# STM32U585xx register map
File version: 1.0
Registers are 32-bit, read-write, reset 0x0 unless marked. A register's access mark holds for its fields unless they carry their own. Offsets are from the block's base; [hi:lo] are bit positions; {n}, {i} and the like mark numbered series.

## PSSI
Base 0x4202C400
Same registers: PSSI_S 0x5202C400
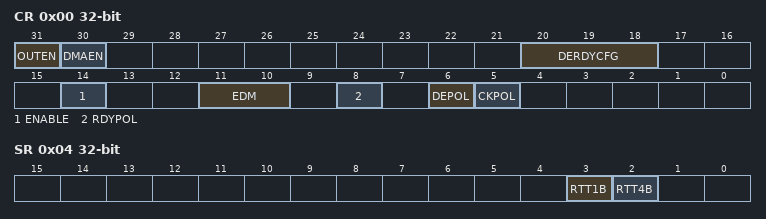
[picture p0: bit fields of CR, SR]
0x00 CR — PSSI control register
  [31] OUTEN — Data direction selection
  [30] DMAEN — DMA enable
  [20:18] DERDYCFG — Data enable and ready configuration
  [14] ENABLE — PSSI enable
  [11:10] EDM — Extended data mode
  [8] RDYPOL — Ready polarity
  [6] DEPOL — Data enable polarity
  [5] CKPOL — Parallel data clock polarity
0x04 SR — PSSI status register
  [3] RTT1B — Ready to transfer one byte
  [2] RTT4B — Ready to transfer four bytes
0x08 RIS — PSSI raw interrupt status register
  [1] OVR_RIS — Data buffer overrun/underrun raw interrupt status
0x0C IER — PSSI interrupt enable register
  [1] OVR_IE — Data buffer overrun/underrun interrupt enable
0x10 MIS — PSSI masked interrupt status register
  [1] OVR_MIS — Data buffer overrun/underrun masked interrupt status
0x14 ICR — PSSI interrupt clear register
  [1] OVR_ISC — Data buffer overrun/underrun interrupt status clear
0x28 DR — PSSI data register
  [31:0] DR — Data register

## AES — AES hardware accelerator
Base 0x420C0000
Same registers: SAES 0x420C0C00, AES_S 0x520C0000, SAES_S 0x520C0C00
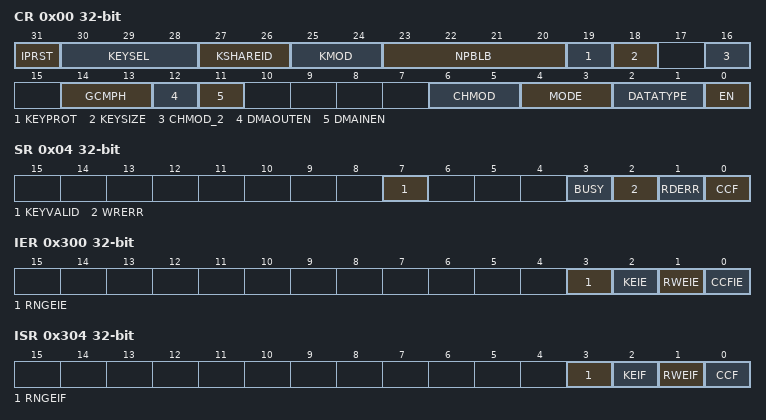
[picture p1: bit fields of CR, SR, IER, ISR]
0x00 CR — AES control register
  [31] IPRST — AES IP software reset
  [30:28] KEYSEL — Key Selection
  [27:26] KSHAREID — Key Shared ID
  [25:24] KMOD — Key mode selection
  [23:20] NPBLB — Number of padding bytes in payload last block
  [19] KEYPROT — Key protection
  [18] KEYSIZE — Key size selection
  [16] CHMOD_2 — AES Chaining Mode
  [14:13] GCMPH — GCM Phase
  [12] DMAOUTEN — Enable data output phase DMA management
  [11] DMAINEN — Enable data input phase DMA management
  [6:5] CHMOD — AES Chaining Mode
  [4:3] MODE — AES Mode Of Operation
  [2:1] DATATYPE — Data type selection
  [0] EN — AES Enable
0x04 SR — AES status register
  [7] KEYVALID — KEYVALID Flag
  [3] BUSY — Busy Flag
  [2] WRERR — Write Error Flag
  [1] RDERR — Read Error Flag
  [0] CCF — Computation Complete Flag
0x08 DINR — AES data input register
  [31:0] DINR — AES Data Input Register
0x0C DOUTR — AES data output register
  [31:0] DOUTR — AES Data Output Register
{0x10+4i} KEYR{i} (i=0..3) — AES key register {i}
  [31:0] KEYR{i} — AES Key Register {i}
{0x20+4i} IVR{i} (i=0..3) — AES initialization vector register {i}
  [31:0] IVR{i} — AES Initialization Vector Register {i}
{0x20+4i} KEYR{i} (i=4..7) — AES key register {i}
  [31:0] KEYR{i} — AES Key Register {i}
{0x40+4i} SUSP{i}R (i=0..7) — AES Suspend register {i}
  [31:0] SUSP{i}R — AES Suspend registers {i}
0x300 IER — AES Interrupt Enable Register
  [3] RNGEIE — Rng error interrupt enable
  [2] KEIE — Key error interrupt enable
  [1] RWEIE — Read or write error Interrupt Enable
  [0] CCFIE — Computation complete flag interrupt enable
0x304 ISR — AES Interrupt Status Register
  [3] RNGEIF — Rng error interrupt flag
  [2] KEIF — Key error interrupt flag
  [1] RWEIF — Read or write error Interrupt flag
  [0] CCF — Computation complete flag
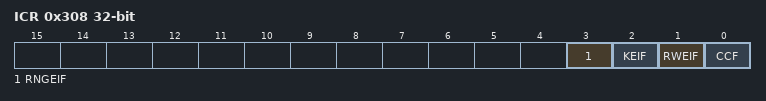
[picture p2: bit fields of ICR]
0x308 ICR — AES Interrupt Clear Register
  [3] RNGEIF — Rng error interrupt flag clear
  [2] KEIF — Key error interrupt flag clear
  [1] RWEIF — Read or write error Interrupt flag clear
  [0] CCF — Computation complete flag clear

## HASH
Base 0x420C0400
Same registers: HASH_S 0x520C0400
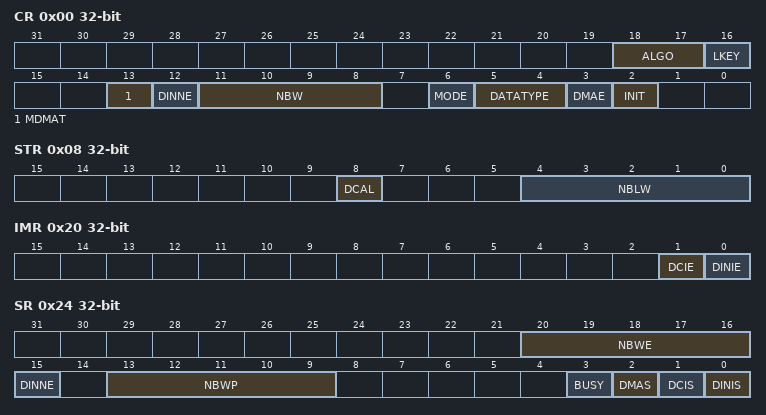
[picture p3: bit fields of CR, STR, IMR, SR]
0x00 CR — HASH control register
  [18:17] ALGO, [16] LKEY, [13] MDMAT, [12] DINNE, [11:8] NBW, [6] MODE, [5:4] DATATYPE, [3] DMAE, [2] INIT
0x04 DIN — HASH data input register
0x08 STR — HASH start register
  [8] DCAL, [4:0] NBLW
{0xC+4i} HR{i} (i=0..4) — HASH digest registers
0x20 IMR — HASH interrupt enable register
  [1] DCIE, [0] DINIE
0x24 SR — HASH status register
  [20:16] NBWE, [15] DINNE, [13:9] NBWP, [3] BUSY, [2] DMAS, [1] DCIS, [0] DINIS
{0xF8+4i} CSR{i} (i=0..53) — HASH context swap registers
{0x310+4i} DIGEST_HR{i} (i=0..7) — HASH digest registers
